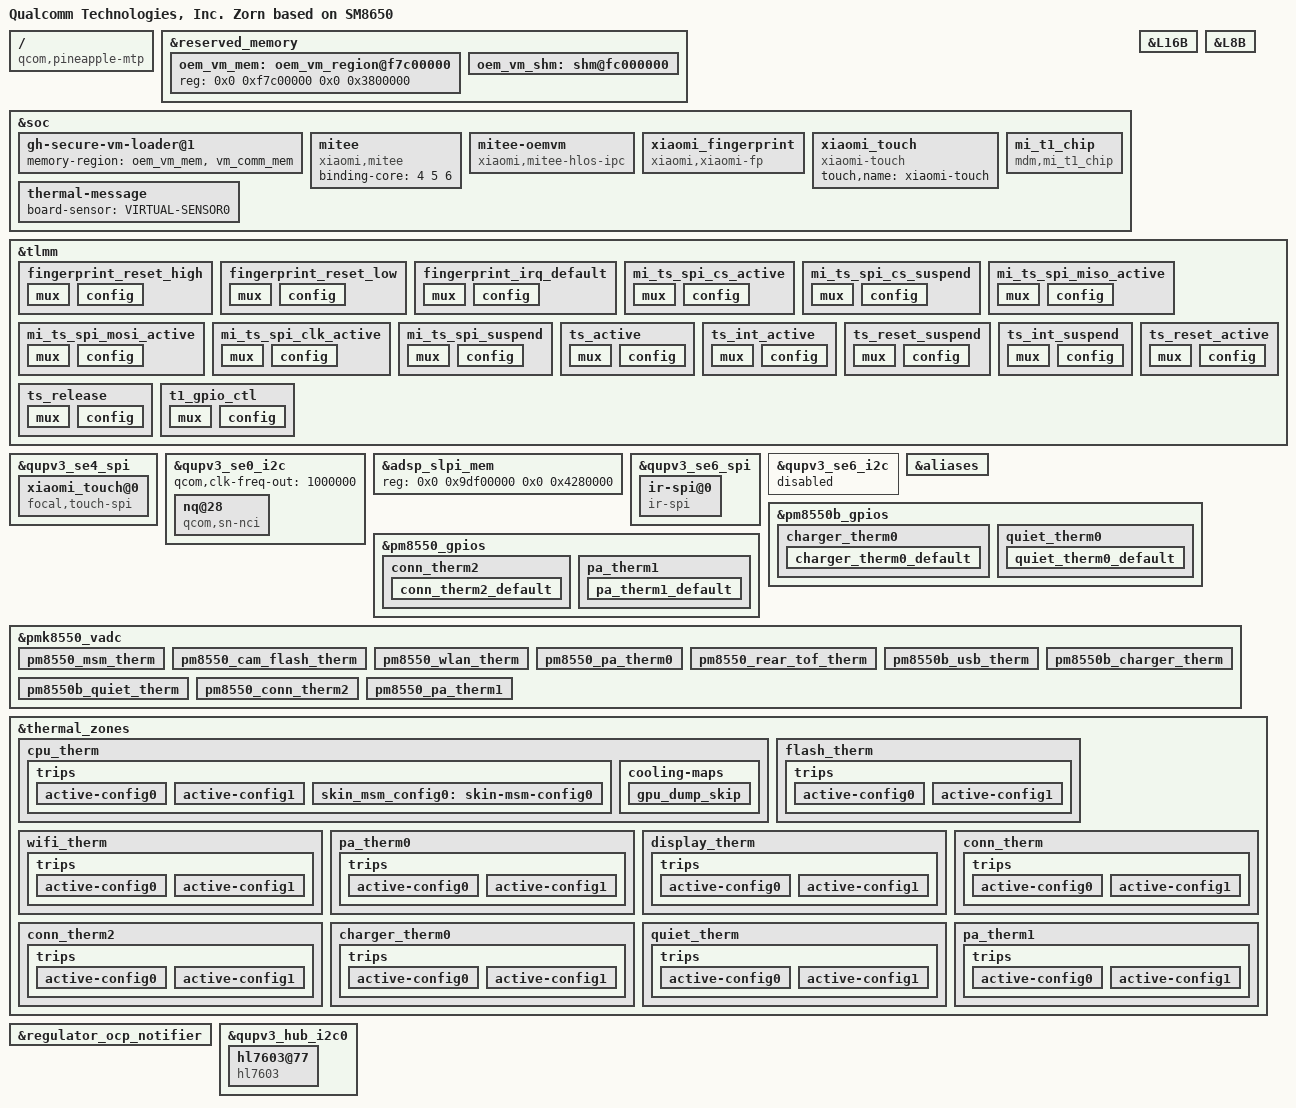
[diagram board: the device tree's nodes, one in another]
/*
  this file is for attribution only of zorn
  And public attribution of xiaomi platforms(like N11U and so and)
*/
#include "zorn-pinctrl.dtsi"
#include "xiaomi-sm8650-common.dtsi"

/ {
	model = "Qualcomm Technologies, Inc. Zorn based on SM8650";
	compatible = "qcom,pineapple-mtp", "qcom,pineapple", "qcom,pineapplep-mtp", "qcom,pineapplep", "qcom,mtp";
	qcom,msm-id = <557 0x10000>, <557 0x20000>, <577 0x10000>, <577 0x20000>;
	qcom,board-id = <8 0>;
	xiaomi,miboard-id = <0xd 0>;
};

/* mitee vm */
&reserved_memory {
	oem_vm_mem: oem_vm_region@f7c00000 {
		reg = <0x0 0xf7c00000 0x0 0x3800000>;
	};

	oem_vm_shm: shm@fc000000 {
		no-map;
		reg = <0x0 0xfc000000 0x0 0x400000>;
		gunyah-label = <0x3>;
	};
};

&soc {
	gh-secure-vm-loader@1 {
		memory-region = <&oem_vm_mem &vm_comm_mem>;
	};

	mitee: mitee {
		compatible = "xiaomi,mitee";
		binding-core = <4 5 6>;
	};

	mitee-oemvm {
		compatible = "xiaomi,mitee-hlos-ipc";
		xiaomi,master;
		gunyah-shm-label = <0x3>;
		peer-name = <0x4>;
		shared-buffer = <&oem_vm_shm>;
	};
};
/* mitee vm */

&soc {
	xiaomi_fingerprint {
		compatible = "xiaomi,xiaomi-fp";
		xiaomi,gpio_irq = <&tlmm 90 0x0>;
		xiaomi,gpio_ipc = <&tlmm 90 0x0>;
		xiaomi,gpio_intr2 = <&tlmm 89 0x0>;
		fp_3v3_vreg-supply = <&L16B>;
		fp_1v8_vreg-supply = <&L8B>;
		netlink-event = <25>;
		sensor-loc = <606 2361 834 2589>;
		pinctrl-names = "reset_high", "reset_low","irq_default";
		pinctrl-0 = <&fingerprint_reset_high>;
		pinctrl-1 = <&fingerprint_reset_low>;
		pinctrl-2 = <&fingerprint_irq_default>;
		status = "ok";
	};

	xiaomi_touch {
		compatible = "xiaomi-touch";
		status = "ok";
		touch,name = "xiaomi-touch";
	};

	mi_t1_chip {
		compatible = "mdm,mi_t1_chip";
		gpio-count = <2>;
		first-gpio = <22>;
		mi-t1-gpio-1 = <&tlmm 22 0x0>;
		mi-t1-gpio-2 = <&tlmm 21 0x0>;
		pinctrl-0 = <&t1_gpio_ctl>;
	};

	thermal-message {
 		board-sensor = "VIRTUAL-SENSOR0";
	};
};

&L16B {
	regulator-min-microvolt = <3300000>;
	regulator-max-microvolt = <3300000>;
	qcom,init-voltage = <3300000>;
};

&L8B {
	regulator-min-microvolt = <1800000>;
	regulator-max-microvolt = <1800000>;
	qcom,init-voltage = <1800000>;
};

&tlmm {
	/* FP_RESET_HIGH, state device active*/
	fingerprint_reset_high: fingerprint_reset_high {
		mux {
			pins = "gpio89";
			function = "gpio";
		};
		config {
			pins = "gpio89";
			drive-strength = <2>;
			bias-disable;
			output-high;
		};
	};
	/* FP_RESET_LOW */
	fingerprint_reset_low: fingerprint_reset_low {
		mux {
			pins = "gpio89";
			function = "gpio";
		};
		config {
			pins = "gpio89";
			drive-strength = <2>;
			bias-disable;
			output-low;
		};
	};
	/* FP_INT_N */
	fingerprint_irq_default: fingerprint_irq_default {
		mux {
			pins = "gpio90";
			function = "gpio";
		};
		config {
			pins = "gpio90";
			drive-strength = <2>;
			bias-pull-down;
		};
	};

	mi_ts_spi_cs_active: mi_ts_spi_cs_active {
		mux {
			pins = "gpio51";
			function = "qup1_se4_l3";
		};

		config {
			pins = "gpio51";
			drive-strength = <16>;
			bias-disable;
			output-high;
		};
	};

	mi_ts_spi_cs_suspend: mi_ts_spi_cs_suspend {
		mux {
			pins = "gpio51";
			function = "gpio";
		};

		config {
			pins = "gpio51";
			drive-strength = <16>;
			bias-disable;
			output-low;
		};
	};

	mi_ts_spi_miso_active: mi_ts_spi_miso_active {
		mux {
			pins = "gpio48";
			function = "qup1_se4_l0";
		};
		config {
			pins = "gpio48";
			drive-strength = <6>;
			bias-disable;
		};
	};

	mi_ts_spi_mosi_active: mi_ts_spi_mosi_active {
		mux {
			pins = "gpio49";
			function = "qup1_se4_l1";
		};
		config {
			pins = "gpio49";
			drive-strength = <6>;
			bias-disable;
		};
	};

	mi_ts_spi_clk_active: mi_ts_spi_clk_active {
		mux {
			pins = "gpio50";
			function = "qup1_se4_l2";
		};
		config {
			pins = "gpio50";
			drive-strength = <6>;
			bias-disable;
		};
	};

	mi_ts_spi_suspend: mi_ts_spi_suspend {
		mux {
			pins = "gpio48", "gpio49", "gpio50";
			function = "gpio";
		};

		config {
			pins = "gpio48", "gpio49", "gpio50";
			drive-strength = <6>;
			bias-disable;
		};
	};

	ts_active: ts_active {
		mux {
			pins = "gpio161", "gpio162";
			function = "gpio";
		};

		config {
			pins = "gpio161", "gpio162";
			drive-strength = <8>;
			bias-pull-up;
		};
	};

	ts_int_active: ts_int_active {
		mux {
			/* GPIO 162 Interrupt */
			pins = "gpio162";
			function = "gpio";
		};

		config {
			pins = "gpio162";
			input-enable;
			bias-disable;
		};
	};

	ts_reset_suspend: ts_reset_suspend {
		mux {
			pins = "gpio161";
			function = "gpio";
		};

		config {
			pins = "gpio161";
			drive-strength = <2>;
			bias-pull-down;
		};
	};

	ts_int_suspend: ts_int_suspend {
		mux {
			pins = "gpio162";
			function = "gpio";
		};

		config {
			pins = "gpio162";
			drive-strength = <2>;
			bias-disable;
		};
	};

	ts_reset_active: ts_reset_active {
		mux {
			/* GPIO 161 Interrupt */
			pins = "gpio161";
			function = "gpio";
		};

		config {
			pins = "gpio161";
			drive-strength = <8>;
			bias-pull-up;
		};
	};

	ts_release: ts_release {
		mux {
			pins = "gpio161", "gpio162";
			function = "gpio";
		};

		config {
			pins = "gpio161", "gpio162";
			drive-strength = <2>;
			bias-disable;
		};
	};

	t1_gpio_ctl: t1_gpio_ctl {
		mux {
			pins = "gpio22", "gpio21";
			function = "gpio";
		};
		config {
			pins = "gpio22", "gpio21";
			drive-strength = <2>;
			bias-disable;
			output-enable;
		};
	};
};

&qupv3_se4_spi {
	status = "ok";
	qcom,rt;
	qcom,la-vm;
	pinctrl-0 = <&mi_ts_spi_mosi_active>, <&mi_ts_spi_miso_active>,
			<&mi_ts_spi_clk_active>, <&mi_ts_spi_cs_active>;
	pinctrl-1 = <&mi_ts_spi_suspend>, <&mi_ts_spi_cs_suspend>;
	xiaomi_touch@0 {
		status = "ok";
		compatible = "focal,touch-spi";
		reg = <0x0>;
		spi-max-frequency = <15000000>;
		interrupt-parent = <&tlmm>;
		interrupts = <162 0x2008>;

		pinctrl-names = "pmx_ts_active", "pmx_ts_suspend";
		pinctrl-0 = <&ts_reset_active &ts_int_active>;
		pinctrl-1 = <&ts_int_suspend &ts_reset_suspend>;

		focaltech,avdd-name = "avdd";
		avdd-supply = <&L14B>;
		focaltech,iovdd-name = "iovdd";
		iovdd-supply = <&L12B>;

		focaltech,irq-gpio = <&tlmm 162 0x2008>;
		focaltech,reset-gpio = <&tlmm 161 0x00>;
		focaltech,max-touch-number = <10>;
		focaltech,super-resolution-factors = <100>;
		focaltech,display-coords =  <0 0 143999 319999>;
		focaltech,touch-range-array = <1 5 10 15 20>;
		focaltech,touch-def-array = <3 3 3 3>;
		focaltech,touch-expert-array = <10 10 10 10
						20 20 15 10
						20 20 20 10>;

		focaltech,support-fod = <1>;
		focaltech,fod-lx=<607>;
		focaltech,fod-ly=<2389>;
		focaltech,fod-x-size=<226>;
		focaltech,fod-y-size=<226>;
		focaltech,max-x = <1440>;
		focaltech,max-y = <3200>;
		focaltech,rx-num = <18>;
		focaltech,tx-num = <40>;

		mi_tp,game-mode-array =
				<1 0 0 0 0>;  /* MAX MIN DEF SET GET */
		mi_tp,active-mode-array =
				<1 0 0 0 0>;  /* MAX MIN DEF SET GET */
		mi_tp,tolerance-array =
				<4 0 2 2 2>;  /* MAX MIN DEF SET GET */
		mi_tp,up-threshold-array =
				<4 0 3 3 3>;  /* MAX MIN DEF SET GET */
		mi_tp,aim-sensitivity-array =
				<4 0 2 2 2>;  /* MAX MIN DEF SET GET */
		mi_tp,tap-stability-array =
				<4 0 2 2 2>;  /* MAX MIN DEF SET GET */
		mi_tp,edge-filter-array =
				<3 0 2 2 2>;  /* MAX MIN DEF SET GET */
		mi_tp,panel-orien-array =
				<3 0 0 0 0>;  /* MAX MIN DEF SET GET */
		mi_tp,report-rate-array =
				<3 0 0 0 0>;  /* MAX MIN DEF SET GET */
		mi_tp,expert-mode-array =
				<3 1 1 1 1>;  /* MAX MIN DEF SET GET */
	};
};

&qupv3_se0_i2c {
	status = "ok";
	qcom,clk-freq-out = <1000000>;
	#address-cells = <1>;
	#size-cells = <0>;
	nq@28 {
		compatible = "qcom,sn-nci";
		reg = <0x28>;
		qcom,sn-irq = <&tlmm 75 0x00>;
		qcom,sn-ven = <&tlmm 34 0x00>;
		qcom,sn-clkreq = <&tlmm 35 0x00>;
		qcom,sn-szone = "enable";
		qcom,sn-vdd-1p8-supply = <&L3C>;
		qcom,sn-vdd-1p8-voltage = <1200000 1200000>;
		qcom,sn-vdd-1p8-current = <157000>;
		interrupt-parent = <&tlmm>;
		interrupts = <75 0>;
		interrupt-names = "nfc_irq";
		pinctrl-names = "nfc_active", "nfc_suspend";
		pinctrl-0 = <&nfc_int_active &nfc_enable_active>;
		pinctrl-1 = <&nfc_int_suspend &nfc_enable_suspend>;
	};
};

&adsp_slpi_mem {
        reg = <0x0 0x9df00000 0x0 0x4280000>;
};

&qupv3_se6_spi {
	status = "ok";
	ir-spi@0 {
		compatible = "ir-spi";
		reg = <0>;
		spi-max-frequency = <19200000>;
		status = "ok";
	};
};

&qupv3_se6_i2c {
	status = "disabled";
};

&aliases {
	spi2 = "/soc/qcom,qupv3_1_geni_se@ac0000/spi@a90000";
};

&pm8550b_gpios {
	charger_therm0 {
		charger_therm0_default: charger_therm0_default {
		pins = "gpio10";
		bias-high-impedance;
		};
	};
};

&pm8550b_gpios {
	quiet_therm0 {
		quiet_therm0_default: quiet_therm0_default {
		pins = "gpio12";
		bias-high-impedance;
		};
	};
};

&pm8550_gpios {
	conn_therm2 {
		conn_therm2_default: conn_therm2_default {
		pins = "gpio4";
		bias-high-impedance;
		};
	};
};

&pm8550_gpios {
	pa_therm1 {
		pa_therm1_default: pa_therm1_default {
		pins = "gpio3";
		bias-high-impedance;
		};
	};
};

&pmk8550_vadc {
	pinctrl-names = "default";
	pinctrl-0 = <&conn_therm2_default>, <&charger_therm0_default>,<&pa_therm1_default>,<&quiet_therm0_default>;

	pm8550_msm_therm {
		reg = <PM8550_ADC5_GEN3_AMUX_THM1_100K_PU>;
		label = "pm8550_msm_therm";
		qcom,ratiometric;
		qcom,hw-settle-time = <200>;
		qcom,pre-scaling = <1 1>;
		qcom,adc-tm-type = <1>;
	};

	pm8550_cam_flash_therm {
		reg = <PM8550_ADC5_GEN3_AMUX_THM2_100K_PU>;
		label = "pm8550_cam_flash_therm";
		qcom,ratiometric;
		qcom,hw-settle-time = <200>;
		qcom,pre-scaling = <1 1>;
		qcom,adc-tm-type = <1>;
	};

	pm8550_wlan_therm {
		reg = <PM8550_ADC5_GEN3_AMUX_THM3_100K_PU>;
		label = "pm8550_wlan_therm";
		qcom,ratiometric;
		qcom,hw-settle-time = <200>;
		qcom,pre-scaling = <1 1>;
		qcom,adc-tm-type = <1>;
	};

	pm8550_pa_therm0 {
		reg = <PM8550_ADC5_GEN3_AMUX_THM4_100K_PU>;
		label = "pm8550_pa_therm_0";
		qcom,ratiometric;
		qcom,hw-settle-time = <200>;
		qcom,pre-scaling = <1 1>;
		qcom,adc-tm-type = <1>;
	};

	pm8550_rear_tof_therm {
		reg = <PM8550_ADC5_GEN3_AMUX_THM5_100K_PU>;
		label = "pm8550_rear_tof_therm";
		qcom,ratiometric;
		qcom,hw-settle-time = <200>;
		qcom,pre-scaling = <1 1>;
		qcom,adc-tm-type = <1>;
	};

	pm8550b_usb_therm {
		reg = <PM8550B_ADC5_GEN3_AMUX_THM4_USB_THERM_100K_PU>;
		label = "pm8550b_usb_therm";
		qcom,ratiometric;
		qcom,hw-settle-time = <200>;
		qcom,pre-scaling = <1 1>;
		qcom,adc-tm-type = <1>;
	};

	pm8550b_charger_therm {
		reg = <PM8550B_ADC5_GEN3_AMUX_THM6_GPIO10_100K_PU>;
		label = "pm8550b_charger_therm";
		qcom,ratiometric;
		qcom,pre-scaling = <1 1>;
		qcom,adc-tm-type = <1>;
	};

	pm8550b_quiet_therm {
 		reg = <PM8550B_ADC5_GEN3_AMUX4_GPIO12_100K_PU>;
		label = "pm8550b_quiet_therm";
		qcom,ratiometric;
		qcom,pre-scaling = <1 1>;
		qcom,adc-tm-type = <1>;
        };

	pm8550_conn_therm2 {
 		reg = <PM8550_ADC5_GEN3_AMUX2_GPIO4_100K_PU>;
 		label = "pm8550_conn_therm2";
 		qcom,ratiometric;
 		qcom,hw-settle-time = <200>;
 		qcom,pre-scaling = <1 1>;
 		qcom,adc-tm-type = <1>;
 	};

	pm8550_pa_therm1 {
 		reg = <PM8550_ADC5_GEN3_AMUX1_GPIO3_100K_PU>;
 		label = "pm8550_pa_therm1";
 		qcom,ratiometric;
 		qcom,hw-settle-time = <200>;
 		qcom,pre-scaling = <1 1>;
 		qcom,adc-tm-type = <1>;
 	};
};

&thermal_zones {
	cpu_therm {
		polling-delay-passive = <0>;
		polling-delay = <0>;
		thermal-sensors = <&pmk8550_vadc PM8550_ADC5_GEN3_AMUX_THM1_100K_PU>;
		trips {
			active-config0 {
				temperature = <125000>;
				hysteresis = <1000>;
				type = "passive";
			};

			active-config1 {
				temperature = <125000>;
				hysteresis = <1000>;
				type = "passive";
			};

			skin_msm_config0: skin-msm-config0 {
				temperature = <60000>;
				hysteresis = <10000>;
				type = "passive";
			};
		};
		cooling-maps {
			gpu_dump_skip {
				trip = <&skin_msm_config0>;
				cooling-device = <&gpu_dump_skip_cdev 1 1>;
			};
		};
	};

	flash_therm {
		polling-delay-passive = <0>;
		polling-delay = <0>;
		thermal-sensors = <&pmk8550_vadc PM8550_ADC5_GEN3_AMUX_THM2_100K_PU>;
		trips {
			active-config0 {
				temperature = <125000>;
				hysteresis = <1000>;
				type = "passive";
			};

			active-config1 {
				temperature = <125000>;
				hysteresis = <1000>;
				type = "passive";
			};
		};
	};

	wifi_therm {
		polling-delay-passive = <0>;
		polling-delay = <0>;
		thermal-sensors = <&pmk8550_vadc PM8550_ADC5_GEN3_AMUX_THM3_100K_PU>;
		trips {
			active-config0 {
				temperature = <125000>;
				hysteresis = <1000>;
				type = "passive";
			};

			active-config1 {
				temperature = <125000>;
				hysteresis = <1000>;
				type = "passive";
			};
		};
	};

	pa_therm0 {
		polling-delay-passive = <0>;
		polling-delay = <0>;
		thermal-sensors = <&pmk8550_vadc PM8550_ADC5_GEN3_AMUX_THM4_100K_PU>;
		trips {
			active-config0 {
				temperature = <125000>;
				hysteresis = <1000>;
				type = "passive";
			};

			active-config1 {
				temperature = <125000>;
				hysteresis = <1000>;
				type = "passive";
			};
		};
	};

	display_therm {
		polling-delay-passive = <0>;
		polling-delay = <0>;
		thermal-sensors = <&pmk8550_vadc PM8550_ADC5_GEN3_AMUX_THM5_100K_PU>;
		trips {
			active-config0 {
				temperature = <125000>;
				hysteresis = <1000>;
				type = "passive";
			};

			active-config1 {
				temperature = <125000>;
				hysteresis = <1000>;
				type = "passive";
			};
		};
	};

	conn_therm {
		polling-delay-passive = <0>;
		polling-delay = <0>;
		thermal-sensors = <&pmk8550_vadc PM8550B_ADC5_GEN3_AMUX_THM4_USB_THERM_100K_PU>;
		trips {
			active-config0 {
				temperature = <125000>;
				hysteresis = <1000>;
				type = "passive";
			};

			active-config1 {
				temperature = <125000>;
				hysteresis = <1000>;
				type = "passive";
			};
		};
	};

	conn_therm2 {
		polling-delay-passive = <0>;
		polling-delay = <0>;
		thermal-sensors = <&pmk8550_vadc PM8550_ADC5_GEN3_AMUX2_GPIO4_100K_PU>;
		trips {
			active-config0 {
				temperature = <125000>;
				hysteresis = <1000>;
				type = "passive";
			};

			active-config1 {
				temperature = <125000>;
				hysteresis = <1000>;
				type = "passive";
			};
		};
	};

	charger_therm0 {
		polling-delay-passive = <0>;
		polling-delay = <0>;
		thermal-sensors = <&pmk8550_vadc PM8550B_ADC5_GEN3_AMUX_THM6_GPIO10_100K_PU>;
		trips {
			active-config0 {
				temperature = <125000>;
				hysteresis = <1000>;
				type = "passive";
			};

			active-config1 {
				temperature = <125000>;
				hysteresis = <1000>;
				type = "passive";
			};
		};
	};

	quiet_therm {
		polling-delay-passive = <0>;
		polling-delay = <0>;
		thermal-sensors = <&pmk8550_vadc PM8550B_ADC5_GEN3_AMUX4_GPIO12_100K_PU>;
		trips {
			active-config0 {
				temperature = <125000>;
				hysteresis = <1000>;
				type = "passive";
			};
			active-config1 {
				temperature = <125000>;
				hysteresis = <1000>;
				type = "passive";
			};
		};
	};

	pa_therm1 {
		polling-delay-passive = <0>;
		polling-delay = <0>;
		thermal-sensors = <&pmk8550_vadc PM8550_ADC5_GEN3_AMUX1_GPIO3_100K_PU>;
		trips {
			active-config0 {
				temperature = <125000>;
				hysteresis = <1000>;
				type = "passive";
			};
			active-config1 {
				temperature = <125000>;
				hysteresis = <1000>;
				type = "passive";
			};
		};
	};
};

/*Remove PM8010 N for hardware design*/
&regulator_ocp_notifier {
	/delete-property/ periph-d40-supply;
	/delete-property/ periph-d41-supply;
	/delete-property/ periph-d42-supply;
	/delete-property/ periph-d43-supply;
	/delete-property/ periph-d44-supply;
	/delete-property/ periph-d45-supply;
	/delete-property/ periph-d46-supply;
};

&qupv3_hub_i2c0 {
	status = "ok";
	hl7603@77 {
		compatible = "hl7603";
		reg = <0x77>;
		vout_threshold = <3400>;
	};
};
